# RL6955_IP_SVD register map
Vendor: Realtek
Registers are 32-bit, read-write, reset 0x0 unless marked. A register's access mark holds for its fields unless they carry their own. Offsets are from the block's base; [hi:lo] are bit positions; lines under a group give offsets from that group; {n}, {i} and the like mark numbered series; <NAME> marks a mode.

## SYSTEM_TZ_CTRL_BASE
Base 0x41000000
Same registers: LP_SYS_1 0x41000200
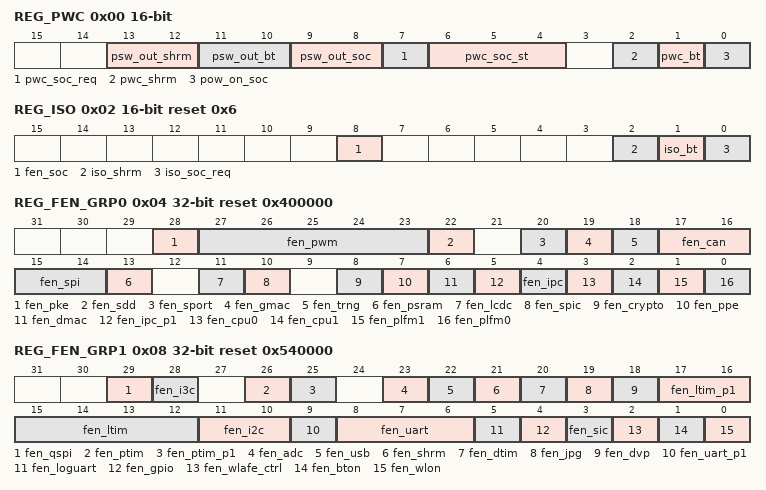
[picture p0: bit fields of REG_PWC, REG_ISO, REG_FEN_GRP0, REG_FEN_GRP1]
0x00 REG_PWC 16-bit access per field
  [13:12] psw_out_shrm ro — ShareMem domain power switch status 1: power on 0: power off Note:there are two group
  [11:10] psw_out_bt ro — BT domain power switch status 1: power on 0: power off Note:there are two group
  [9:8] psw_out_soc ro — SOC domain power switch status 1: power on 0: power off Note:there are two group
  [7] pwc_soc_req ro — pwc soc req arb result
  [6:4] pwc_soc_st ro — pwc soc arb result state
  [2] pwc_shrm rw — BT share mem power cut control 1: Enable BT share mem power (mux + mbis + cell) 0: Disable
  [1] pwc_bt rw — This is BT function total power cut control 1: Enable BT power cut 0: Disable
  [0] pow_on_soc rw — 1:SYS PMC request to enable HP SOC power cut and diable ISO 0: SYS PMC request to disable HP SOC power cut and enable ISO
0x02 REG_ISO 16-bit access per field reset 0x6
  [8] fen_soc rw — 1: enable hs soc sytem 0: disable hs soc system (Note: used as soc power on reset)
  [2] iso_shrm rw — 1: isolate signals from PD_SHRM to other power domain 0: release iso
  [1] iso_bt rw — 1: isolate signals from PD_BT to other power domain 0: release iso
  [0] iso_soc_req ro — isolate signals from PD_SOC to other power domain. It is arb result
0x04 REG_FEN_GRP0 reset 0x400000
  [28] fen_pke — 1: enable pke module 0: reset No use
  [27:23] fen_pwm — 1: enable PWM TIMER function 0: disable [4:1]:pwm [0]:pulse
  [22] fen_sdd — 1: enable sdio device function 0: disable
  [20] fen_sport — 1: enable SPORT function 0: disable
  [19] fen_gmac — 1: enable ppe module 0: reset No use
  [18] fen_trng — 1: enable TRNG function 0: disable
  [17:16] fen_can — 1: enable can0/1 module 0: reset No use
  [15:14] fen_spi — 1: enable SPI1 function 0: disable
  [13] fen_psram — 1: enable PSRAM function 0: disable
  [11] fen_lcdc — 1: enable ppe module 0: reset No use
  [10] fen_spic — Flash spic function enable 1: enable flash 0: disable flash
  [8] fen_crypto — 1: enable IPSEC (AES + HMAC) function 0: disable
  [7] fen_ppe — 1: enable ppe module 0: reset No use
  [6] fen_dmac — 1: enable GDMA function 0: disable
  [5] fen_ipc_p1 — 1: enable IPC function 0: reset
  [4] fen_ipc — 1: enable IPC function 0: reset
  [3] fen_cpu0 — 1: enable cpu0 (KM4TZ) 0: reset
  [2] fen_cpu1 — 1: enable cpu1 (KM4NS) 0: reset
  [1] fen_plfm1 — 1: enable platform1 0: reset
  [0] fen_plfm0 — 1: enable platform0 0: reset
0x08 REG_FEN_GRP1 reset 0x540000
  [29] fen_qspi — 1: enable qspi function 0: disable
  [28] fen_i3c — 1: enable i3c function 0: disable
  [26] fen_ptim — pmc_timer function enable 1: enable 0: disable
  [25] fen_ptim_p1 — pmc_timer function enable 1: enable 0: disable
  [23] fen_adc — lp adc function enable 1: enable 0: disable
  [22] fen_usb — usb core function enable 1: enable 0: disable
  [21] fen_shrm — BT share memory function enable 1: enable 0: disable Note:this is same as PD_SHRM power reset
  [20] fen_dtim — Debug timer function enable 1: enable 0: disable
  [19] fen_jpg — mjpeg function enable 1: enable 0: disable
  [18] fen_dvp — dvp function enable 1: enable 0: disable
  [17:16] fen_ltim_p1 — Basic Timer4-5 function enable for plfm1 1: enable 0: disable
  [15:12] fen_ltim — Basic Timer0-3 function enable for plfm0 1: enable 0: disable
  [11:10] fen_i2c — I2C1 function enable 1: enable 0: disable
  [9] fen_uart_p1 — Uart function enable for BT 1: enable 0: disable
  [8:6] fen_uart — Uart function enable 1: enable 0: disable
  [5] fen_loguart — Uartlog function enable 1: enable 0: disable
  [4] fen_gpio — SGPIO function enable 1: enable 0: disable
  [3] fen_sic — 1: enable SIC function 0: reset
  [2] fen_wlafe_ctrl — WL RFAFE control function enable 1: enable 0: disable
  [1] fen_bton — BTON function enable 1: enable 0: disable
  [0] fen_wlon — WLON function enable 1: enable 0: disable
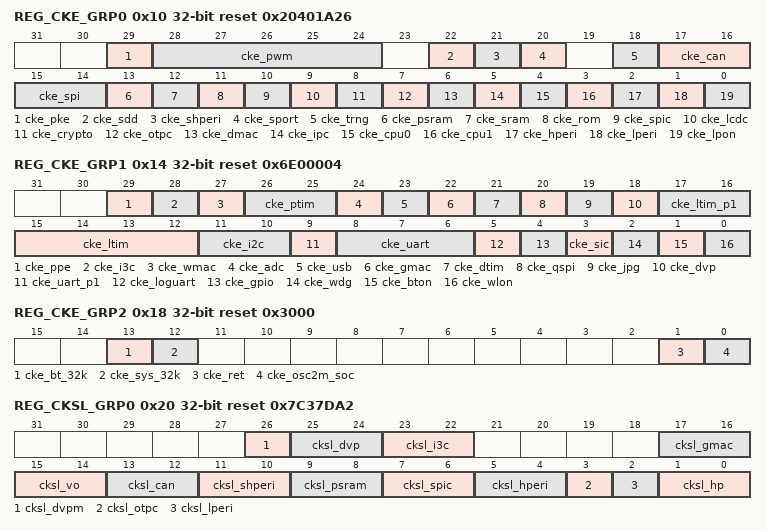
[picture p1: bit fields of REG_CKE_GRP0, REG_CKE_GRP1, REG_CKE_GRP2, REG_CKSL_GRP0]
0x10 REG_CKE_GRP0 reset 0x20401A26
  [29] cke_pke — 1: enable pke clk 0: reset No use
  [28:24] cke_pwm — 1: Enable PWM TIMER clock 0: Disable [1] : pwm timer [0] : pulse timer
  [22] cke_sdd — 1: Enable sdio dev clock 0: Disable
  [21] cke_shperi — 1: Enable shperi clock 0: Disable
  [20] cke_sport — 1: Enable sport clock 0: Disable
  [18] cke_trng — 1: Enable trng bus clock 0: Disable
  [17:16] cke_can — 1: Enable can0/1 bus clock 0: Disable
  [15:14] cke_spi — 1: Enable spi clock 0: Disable
  [13] cke_psram — 1: Enable PSRAM pll divider clock 0: Disable
  [12] cke_sram — 1: Enable sram clock 0: Disable
  [11] cke_rom — 1: Enable rom clock 0: Disable
  [10] cke_spic — 1: Enable FLASH pll divider clock 0: Disable
  [9] cke_lcdc — 1: Enable lcdc pll clock 0: Disable Note: lcdc/mipi all use this cke
  [8] cke_crypto — 1: Enable ipsec (AES + HMAC) clock 0: Disable
  [7] cke_otpc — 1: Enable OTPC clock 0: Disable
  [6] cke_dmac — 1: Enable GDMA0 clock 0: Disable
  [5] cke_ipc — 1: Enable IPC clock 0: Disable
  [4] cke_cpu0 — 1: Enable hp KM4 cpu0 clock 0: Disable
  [3] cke_cpu1 — 1: Enable lp KM4 cpu1 clock 0: Disable
  [2] cke_hperi — 1: Enable HPERI pll divider clock 0: Disable
  [1] cke_lperi — 1: Enable peri_lclk clock all 0: Disable
  [0] cke_lpon — 1.Enable lpon clk 0: Disable Note: this bit is controlled HW PMC, SW shall not modify
0x14 REG_CKE_GRP1 reset 0x6E00004
  [29] cke_ppe — 1: Enable ppe clock 0: Disable
  [28] cke_i3c — 1: Enable i3c clock 0: Disable
  [27] cke_wmac — 1: Enable WMAC AXI and AHB bus clock 0: Disable
  [26:25] cke_ptim — 1: Enable pmc timer clock 0: Disable
  [24] cke_adc — 1: Enable LS ADC clock 0: Disable
  [23] cke_usb — 1: Enable usb core clock 0: Disable
  [22] cke_gmac — 1: Enable gmac clock 0: Disable
  [21] cke_dtim — 1: Enable LS dtim clk 0: Disable
  [20] cke_qspi — 1: Enable qsip clock 0: Disable
  [19] cke_jpg — 1: Enable jpg clock 0: Disable
  [18] cke_dvp — 1: Enable dvp clock 0: Disable
  [17:16] cke_ltim_p1 — LS basic Timer4-5 clk enable for plfm1 0: Disable
  [15:12] cke_ltim — LS basic Timer0-3 clk enable 0: Disable
  [11:10] cke_i2c — 1: Enable HS I2C0 clock 0: Disable [1]: i2c1 [0]: i2c0
  [9] cke_uart_p1 — 1: Enable Uart clock for uart3 0: Disable
  [8:6] cke_uart — 1: Enable Uart clock 0: Disable
  [5] cke_loguart — 1: Enable Uartlog clock 0: Disable
  [4] cke_gpio — 1: Enable GPIO clock 0: Disable
  [3] cke_sic — 1: Enable SIC clock 0: Disable
  [2] cke_wdg — 1: Enable wdg bus clock 0: Disable
  [1] cke_bton — 1: Enable BTON clock 0: Disable
  [0] cke_wlon — 1: Enable WLON clock 0: Disable
0x18 REG_CKE_GRP2 reset 0x3000
  [13] cke_bt_32k — 1.Enable bt 32k enable 0: Disable
  [12] cke_sys_32k — 1.Enable system/wifi 32k enable 0: Disable
  [1] cke_ret — 1.Enable Some IP's clock who has retention function when pmc state change 0: Disable Note: this bit is controlled HW PMC, SW shall not modify
  [0] cke_osc2m_soc — 1.Enable 2M clk path for soc clk 0: Disable Note: this bit is controlled HW PMC, SW shall not modify
0x20 REG_CKSL_GRP0 reset 0x7C37DA2
  [26] cksl_dvpm — dvpm clock select ##0: sys_pll ##1: usb_pll
  [25:24] cksl_dvp — dvp clock select ##x0: xtal ##01: sys_pll ##11: usb_pll
  [23:22] cksl_i3c — i3c clock select ##x0: xtal ##01: sys_pll ##11: usb_pll
  [17:16] cksl_gmac — gmac clock select ##x0: ext50m ##01: sys_pll( 400M for gmac path) ##11: usb_pll
  [15:14] cksl_vo — vo clock select ##x0: xtal ##01: sys_pll ##11: usb_pll
  [13:12] cksl_can — can clock select ##x0: xtal ##01: sys_pll ##11: usb_pll
  [11:10] cksl_shperi — peri_shclk clock select ##x0: xtal ##01: sys_pll ##11: usb_pll
  [9:8] cksl_psram — psram clock select ##x0: xtal ##01: sys_pll ##11: usb_pll
  [7:6] cksl_spic — spic clock select ##x0: xtal ##01: sys_pll ##11: usb_pll
  [5:4] cksl_hperi — hperi clock seletion ##x0: xtal ##01: sys_pll ##11: usb_pll
  [3] cksl_otpc — otpc clock selection ##0: osc4m ##1: xtal Note: this bit will be set by pmc auto, when SW use otp, it will be set to 1
  [2] cksl_lperi — LPERI clock select ##0: osc4m ##1: xtal_40m
  [1:0] cksl_hp — HP clock select,used for KM4 and sram ##x0: xtal ##01: sys_pll ##11: usb_pll
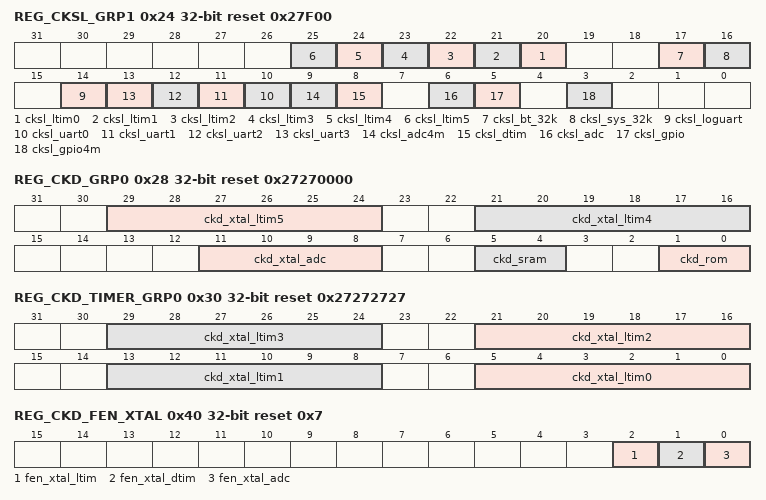
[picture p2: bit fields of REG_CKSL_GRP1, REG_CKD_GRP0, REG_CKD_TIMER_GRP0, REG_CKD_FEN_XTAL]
0x24 REG_CKSL_GRP1 reset 0x27F00
  [n+20] cksl_ltim{n} (n=0..5) — LS timer {n} clock source select ##0: sdm32k ##1: xtal Note:using XTAL divider out , which can be 40M/N (N=2~63)
  [17] cksl_bt_32k — BT 32k clk source selection ##0: osc131k ##1: xtal312p5k
  [16] cksl_sys_32k — system/wifi 32k clk source selection ##0: osc131k ##1: xtal312p5k
  [14] cksl_loguart — Select loguart's input clock ##0: osc4m ##1: xtal
  [n+10] cksl_uart{n} (n=0..3) — Select uart's input rx clock ##0: osc2m ##1: xtal Note:tx input clock is always xtal , and divided in uart IP
  [9] cksl_adc4m — lp adc 4m clk selection ##0: osc4m ##1: xtal Note:when select xtal , it must set divider
  [8] cksl_dtim — dtim clock selection ##0: sdm32k ##1: xtal Note:when select to xtal, it will divided to 1M fixed
  [6] cksl_adc — ADC INT clock selection ##0: bus_clk ##1: ip_clk
  [5] cksl_gpio — GPIO INT clock selecton: ##0: bus_clk ##1: ip_clk
  [3] cksl_gpio4m — gpio ip using 4m clk selection ##0: sdm32k ##1: osc4m
0x28 REG_CKD_GRP0 reset 0x27270000
  [29:24] ckd_xtal_ltim5 — LS timer xtal clock divider when cksl_ltim = 1 0: not support 1: div2 n: divider is n+1 DIV_MIN:1
  [21:16] ckd_xtal_ltim4 — LS timer xtal clock divider when cksl_ltim = 1 0: not support 1: div2 n: divider is n+1 DIV_MIN:1
  [11:8] ckd_xtal_adc — xtal 4m divider for adc Default is /1 which output 40M
  [5:4] ckd_sram — sram clock divider, it is based on hp_clk 0: div1 1: div2 2: div3 3/other: divider by this value + 1 DIV_MIN:0
  [1:0] ckd_rom — rom clock divider, it is based on hp_clk 0: div1 1: div2 2: div3 3/other: divider by this value + 1 DIV_MIN:0
0x30 REG_CKD_TIMER_GRP0 reset 0x27272727
  [8n+5:8n] ckd_xtal_ltim{n} (n=0..3) — LS timer xtal clock divider when cksl_ltim = 1 0: not support 1: div2 n: divider is n+1 DIV_MIN:1
0x34 REG_CKD_TIMER_GRP1 reset 0x270000
  [21:16] ckd_xtal_dtim — xtal 1m divider for dtim Default is /40 which output 1M
0x40 REG_CKD_FEN_XTAL reset 0x7
  [2] fen_xtal_ltim — enable xtal divider for ltim[5:0] use 1:enable 0:disable
  [1] fen_xtal_dtim — enable xtal divider for dtim use 1:enable 0:disable
  [0] fen_xtal_adc — enable xtal divider for adc use 1:enable 0:disable
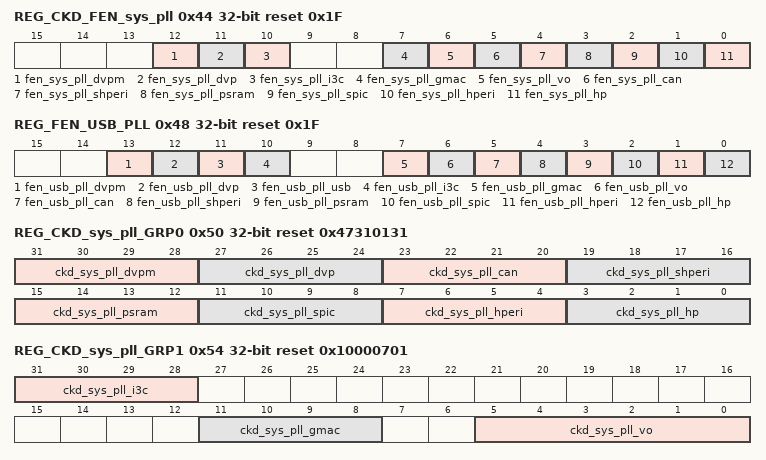
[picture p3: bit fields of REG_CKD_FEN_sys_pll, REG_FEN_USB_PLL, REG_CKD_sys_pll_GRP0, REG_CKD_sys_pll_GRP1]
0x44 REG_CKD_FEN_sys_pll reset 0x1F
  [12] fen_sys_pll_dvpm — sys_pll_divider for dvpm enable 1:enable 0:disable
  [11] fen_sys_pll_dvp — sys_pll_divider for dvp enable 1:enable 0:disable
  [10] fen_sys_pll_i3c — sys_pll_divider for i3c enable 1:enable 0:disable
  [7] fen_sys_pll_gmac — sys_pll_divider for gmac enable 1:enable 0:disable
  [6] fen_sys_pll_vo — sys_pll_divider for vo enable 1:enable 0:disable
  [5] fen_sys_pll_can — sys_pll_divider for can 1:enable 0:disable
  [4] fen_sys_pll_shperi — sys_pll_divider for shperi enable 1:enable 0:disable
  [3] fen_sys_pll_psram — sys_pll_divider for psram enable 1:enable 0:disable
  [2] fen_sys_pll_spic — sys_pll_divider for spic enable 1:enable 0:disable
  [1] fen_sys_pll_hperi — sys_pll_divider for hperi enable 1:enable 0:disable
  [0] fen_sys_pll_hp — sys_pll_divider for hp enable 1:enable 0:disable
0x48 REG_FEN_USB_PLL reset 0x1F
  [13] fen_usb_pll_dvpm — usb_pll_divider for dvpm enable 1:enable 0:disable
  [12] fen_usb_pll_dvp — usb_pll_divider for dvp enable 1:enable 0:disable
  [11] fen_usb_pll_usb — usb_pll divider for usb utim enable 1:enable 0:disable
  [10] fen_usb_pll_i3c — usb_pll_divider for i3c enable 1:enable 0:disable
  [7] fen_usb_pll_gmac — usb_pll_divider for gmac enable 1:enable 0:disable
  [6] fen_usb_pll_vo — usb_pll_divider for vo enable 1:enable 0:disable
  [5] fen_usb_pll_can — usb_pll_divider for can 1:enable 0:disable
  [4] fen_usb_pll_shperi — usb_pll_divider for shperi enable 1:enable 0:disable
  [3] fen_usb_pll_psram — usb_pll_divider for psram enable 1:enable 0:disable
  [2] fen_usb_pll_spic — usb_pll_divider for spic enable 1:enable 0:disable
  [1] fen_usb_pll_hperi — usb_pll_divider for hperi enable 1:enable 0:disable
  [0] fen_usb_pll_hp — usb_pll_divider for hp enable 1:enable 0:disable
0x50 REG_CKD_sys_pll_GRP0 reset 0x47310131
  [31:28] ckd_sys_pll_dvpm — sys_pll divider for shperi 0: div1 1: div2 ... DIV_MIN:0
  [27:24] ckd_sys_pll_dvp — sys_pll divider for shperi 0: div1 1: div2 ... DIV_MIN:0
  [23:20] ckd_sys_pll_can — sys_pll divider for can 0: div1 1: div2 ... Note: default 320M/3=106M DIV_MIN:0
  [19:16] ckd_sys_pll_shperi — sys_pll divider for shperi 0: div1 1: div2 ... DIV_MIN:0
  [15:12] ckd_sys_pll_psram — sys_pll divider for psram 0: Not support 1: div2 ... DIV_MIN:1
  [11:8] ckd_sys_pll_spic — sys_pll divider for spic 0: Not support 1: div2 ... DIV_MIN:1
  [7:4] ckd_sys_pll_hperi — sys_pll divider for hperi 0: Not support 1: div2 ... DIV_MIN:1
  [3:0] ckd_sys_pll_hp — sys_pll divider for hp 0: Not support 1: div2 ... DIV_MIN:1
0x54 REG_CKD_sys_pll_GRP1 reset 0x10000701
  [31:28] ckd_sys_pll_i3c — sys_pll divider for i3c clk 0: div1 1: div2 ... Note: default 200M (for i3c afe clock select 400M) DIV_MIN:0
  [11:8] ckd_sys_pll_gmac — sys_pll divider for vo/panel clk 0: div1 1: div2 ... Note: fix to 50M (for gmac afe clock select 400M) DIV_MIN:0
  [5:0] ckd_sys_pll_vo — sys_pll divider for vo/panel clk 0: div1 1: div2 ... Note: max 200M DIV_MIN:0
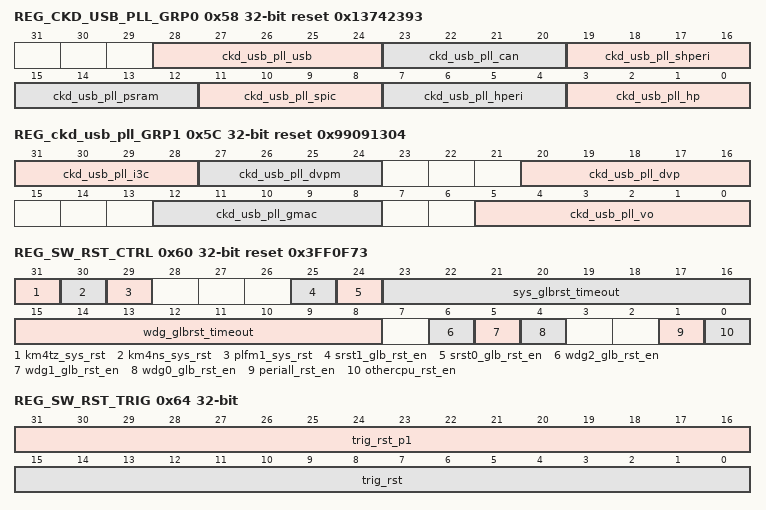
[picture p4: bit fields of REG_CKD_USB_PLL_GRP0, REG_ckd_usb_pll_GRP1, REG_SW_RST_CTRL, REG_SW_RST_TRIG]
0x58 REG_CKD_USB_PLL_GRP0 reset 0x13742393
  [28:24] ckd_usb_pll_usb — usb_pll divider for usb utmi , default 48M 0: div1 1: div2 ... Note: default 960M/8=120M DIV_MIN:0
  [23:20] ckd_usb_pll_can — usb_pll divider for can 0: div1 1: div2 ... Note: default 960M/8=120M DIV_MIN:0
  [19:16] ckd_usb_pll_shperi — usb_pll divider for shperi 0: div1 1: div2 ... DIV_MIN:0
  [15:12] ckd_usb_pll_psram — usb_pll divider for psram, special 400M pll input 0: div1 1: div2 ... DIV_MIN:0
  [11:8] ckd_usb_pll_spic — usb_pll divider for spic 0: div1 1: div2 ... DIV_MIN:0
  [7:4] ckd_usb_pll_hperi — usb_pll divider for hperi 0: div1 1: div2 ...
  [3:0] ckd_usb_pll_hp — usb_pll divider for hp 0: div1 1: div2 ... DIV_MIN:0
0x5C REG_ckd_usb_pll_GRP1 reset 0x99091304
  [31:28] ckd_usb_pll_i3c — usb_pll divider for i3c clk 0: div1 1: div2 ... DIV_MIN:0
  [27:24] ckd_usb_pll_dvpm — usb_pll divider for sdh clk 0: div1 1: div2 ... DIV_MIN:0
  [20:16] ckd_usb_pll_dvp — usb_pll divider for dvp clk 0: div1 1: div2 ... DIV_MIN:0
  [12:8] ckd_usb_pll_gmac — usb_pll divider for gmac, Note: output must fix to 50M.
  [5:0] ckd_usb_pll_vo — usb_pll divider for vo/panel 0: div1 1: div2 ... Note: max 200M DIV_MIN:0
0x60 REG_SW_RST_CTRL reset 0x3FF0F73
  [31] km4tz_sys_rst — Only when REG_SW_RST_TRIG is 0x96969696 , this reg can be write
  [30] km4ns_sys_rst — Only when REG_SW_RST_TRIG is 0x96969696 , this reg can be write
  [29] plfm1_sys_rst — Only when REG_SW_RST_TRIG is 0x96969696 , this reg can be write
  [25] srst1_glb_rst_en — 1.system reset1 will reset all syson IP and local CPU1(km4ns) 0.system reset0 will reset local CPU1(km4ns)
  [24] srst0_glb_rst_en — 1.system reset0 will reset all syson IP and local CPU0(km4tz) 0.system reset0 will reset local CPU0(km4tz)
  [23:16] sys_glbrst_timeout — If system glb rst en is disable , system reset will reset its local cpu only . but if bus is hang , it will trigger global reset also . HW will wait local CPU's status , if it is not in IDLE in a threshold time, it will trigger global reset . Note : This value must set > 1 , it is base on 4M clock cycle .
  [15:8] wdg_glbrst_timeout — If wdg's glb rst en is disable , wdg reset will reset its local cpu only . but if bus is hang , it will trigger global reset also . HW will wait local CPU's status , if it is not in IDLE in a threshold time, it will trigger global reset . Note : This value must set > 1 , it is base on 32k clock cycle .
  [6] wdg2_glb_rst_en — 1.wdg2 will reset all syson IP and local CPU 0.wdg2 will reset local CPU and itself Note: wdg2 's local CPU is CPU0
  [5] wdg1_glb_rst_en — 1.wdg1 will reset all syson IP and local CPU 0.wdg1 will reset local CPU and itself Note: wdg1 's local CPU is CPU0
  [4] wdg0_glb_rst_en — 1.wdg0 will reset all syson IP and local CPU 0.wdg0 will reset local CPU and itself Note: wdg0 's local CPU is CPU1
  [1] periall_rst_en — 1. warm reset request by one cpu will reset all peri and local cpu 0. warm reset request by one cpu will only reset local cpu Note : peri rst will use sysrst mst also
  [0] othercpu_rst_en — 1. warm reset request by one cpu will reset other cpu's core and local cpu 0. warm reset request by one cpu will only reset local cpu
0x64 REG_SW_RST_TRIG
  [31:16] trig_rst_p1 — System reset trigger register Write 0x96969696 to enable the write of reset control Write 0x69696969 will trigger the system if REG_SW_RST_CTRL set .
  [15:0] trig_rst — System reset trigger register Write 0x96969696 to enable the write of reset control Write 0x69696969 will trigger the system if REG_SW_RST_CTRL set .
0x68 REG_BOOT_REASON_SW
  [31:0] dummy
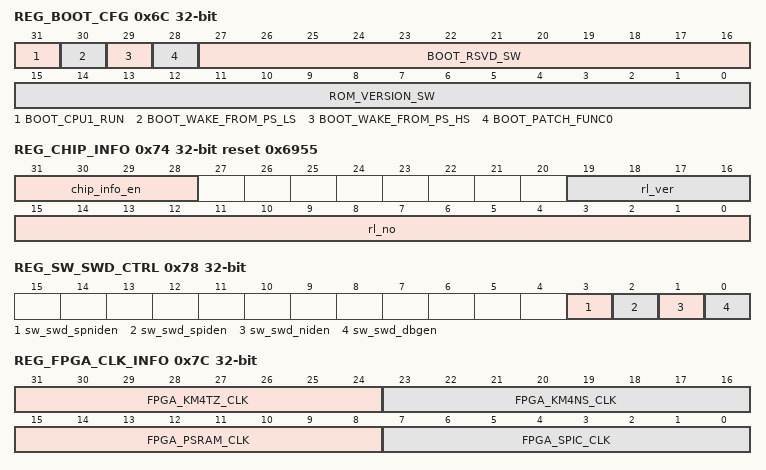
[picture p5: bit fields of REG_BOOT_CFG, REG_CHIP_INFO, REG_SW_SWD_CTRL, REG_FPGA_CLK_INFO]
0x6C REG_BOOT_CFG
  [31] BOOT_CPU1_RUN, [30] BOOT_WAKE_FROM_PS_LS, [29] BOOT_WAKE_FROM_PS_HS, [28] BOOT_PATCH_FUNC0, [27:16] BOOT_RSVD_SW, [15:0] ROM_VERSION_SW
0x70 REG_SW_PATCH
  [31:0] sw_patch_saddr — SW patch code start addr. OTP physical addr 0x500-0x6FF will autoload to this addr .
0x74 REG_CHIP_INFO access per field reset 0x6955
  [31:28] chip_info_en rw — Enable Internal Chip Information display.(Don't move 0x74 address , for code is not auto-gen) 0xA: enable. Others: disable. Note: CHIP_INFO can be read only if CHIP_INFO_EN[3:0]=0xA, otherwise the read result will return 0x0.
  [19:16] rl_ver ro — CHIP cut verison : 0: A-cut 1: B-cut ...
  [15:0] rl_no ro — CHIP RL NUMBER : 0x6955 Note: this field also used by FPGA or Simulation . 0xFFFF: FPGA 0XFFFE: PXP 0xFFF0: IMG Simulation 0 (when simulation , disable loguart for speedup, disable calibration)
0x78 REG_SW_SWD_CTRL
  [3] sw_swd_spniden, [2] sw_swd_spiden, [1] sw_swd_niden, [0] sw_swd_dbgen
0x7C REG_FPGA_CLK_INFO ro
  [31:24] FPGA_KM4TZ_CLK — FPGA KM4TZ clock
  [23:16] FPGA_KM4NS_CLK — FPGA KM4NS clock
  [15:8] FPGA_PSRAM_CLK — FPGA PSRAM clock
  [7:0] FPGA_SPIC_CLK — FPGA SPIC clock
0x80 REG_KM4_XO_CTRL0
  [31:0] init_xo_base
0x84 REG_KM4_XO_CTRL1
  [31:0] init_xo_top
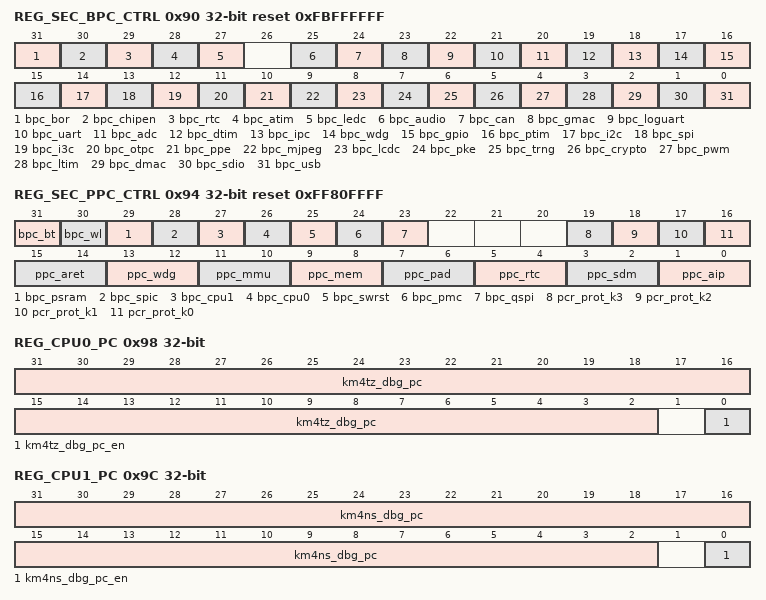
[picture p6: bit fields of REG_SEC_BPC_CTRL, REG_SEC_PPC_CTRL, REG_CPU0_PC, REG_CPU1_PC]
0x90 REG_SEC_BPC_CTRL reset 0xFBFFFFFF
  [31] bpc_bor — Select IP controller source : bor 1:control by nonsec zone 0:control by secure zone
  [30] bpc_chipen — Select IP controller source : chipen 1:control by nonsec zone 0:control by secure zone
  [29] bpc_rtc — Select IP controller source : rtc 1:control by nonsec zone 0:control by secure zone
  [28] bpc_atim — Select IP controller source : atim 1:control by nonsec zone 0:control by secure zone
  [27] bpc_ledc — Select IP controller source : ledc 1:control by nonsec zone 0:control by secure zone
  [25] bpc_audio — Select IP controller source : audio 1:control by nonsec zone 0:control by secure zone
  [24] bpc_can — Select IP controller source : can 1:control by nonsec zone 0:control by secure zone
  [23] bpc_gmac — Select IP controller source : gmac 1:control by nonsec zone 0:control by secure zone
  [22] bpc_loguart — Select IP controller source : loguart 1:control by nonsec zone 0:control by secure zone
  [21] bpc_uart — Select IP controller source : uart 1:control by nonsec zone 0:control by secure zone
  [20] bpc_adc — Select IP controller source : adc4m 1:control by nonsec zone 0:control by secure zone
  [19] bpc_dtim — Select IP controller source : dtim 1:control by nonsec zone 0:control by secure zone
  [18] bpc_ipc — Select IP controller source : ipc 1:control by nonsec zone 0:control by secure zone
  [17] bpc_wdg — Select IP controller source : wdg 1:control by nonsec zone 0:control by secure zone
  [16] bpc_gpio — Select IP controller source : gpio 1:control by nonsec zone 0:control by secure zone
  [15] bpc_ptim — Select IP controller source : ptim 1:control by nonsec zone 0:control by secure zone
  [14] bpc_i2c — Select IP controller source : i2c 1:control by nonsec zone 0:control by secure zone
  [13] bpc_spi — Select IP controller source : spi 1:control by nonsec zone 0:control by secure zone
  [12] bpc_i3c — Select IP controller source : irda 1:control by nonsec zone 0:control by secure zone
  [11] bpc_otpc — Select IP controller source : otpc 1:control by nonsec zone 0:control by secure zone
  [10] bpc_ppe — Select IP controller source : ppe 1:control by nonsec zone 0:control by secure zone
  [9] bpc_mjpeg — Select IP controller source : mjpeg 1:control by nonsec zone 0:control by secure zone
  [8] bpc_lcdc — Select IP controller source : lcdc 1:control by nonsec zone 0:control by secure zone
  [7] bpc_pke — Select IP controller source : pke 1:control by nonsec zone 0:control by secure zone
  [6] bpc_trng — Select IP controller source : trng 1:control by nonsec zone 0:control by secure zone
  [5] bpc_crypto — Select IP controller source : crypto 1:control by nonsec zone 0:control by secure zone
  [4] bpc_pwm — Select IP controller source : pwm 1:control by nonsec zone 0:control by secure zone
  [3] bpc_ltim — Select IP controller source : ltim 1:control by nonsec zone 0:control by secure zone
  [2] bpc_dmac — Select IP controller source : dmac 1:control by nonsec zone 0:control by secure zone
  [1] bpc_sdio — Select IP controller source : sdio 1:control by nonsec zone 0:control by secure zone
  [0] bpc_usb — Select IP controller source : usb 1:control by nonsec zone 0:control by secure zone
0x94 REG_SEC_PPC_CTRL reset 0xFF80FFFF
  [31] bpc_bt — Select IP controller source : bt 1:control by nonsec zone 0:control by secure zone
  [30] bpc_wl — Select IP controller source : wl 1:control by nonsec zone 0:control by secure zone
  [29] bpc_psram — Select IP controller source : psram 1:control by nonsec zone 0:control by secure zone
  [28] bpc_spic — Select IP controller source : spic 1:control by nonsec zone 0:control by secure zone
  [27] bpc_cpu1 — Select IP controller source : cpu1 1:control by nonsec zone 0:control by secure zone
  [26] bpc_cpu0 — Select IP controller source : cpu0 1:control by nonsec zone 0:control by secure zone
  [25] bpc_swrst — Select IP controller source : rst 1:control by nonsec zone 0:control by secure zone
  [24] bpc_pmc — Select IP controller source : pmc 1:control by nonsec zone 0:control by secure zone
  [23] bpc_qspi — Select IP controller source : qspi 1:control by nonsec zone 0:control by secure zone
  [19] pcr_prot_k3 — Retention Mem last forth 256 bit protect 0: read and write , 1 : read only
  [18] pcr_prot_k2 — Retention Mem last third 256 bit protect 0: read and write , 1 : read only
  [17] pcr_prot_k1 — Retention Mem last second 256 bit protect 0: read and write , 1 : read only
  [16] pcr_prot_k0 — Retention Mem last 256 bit protect (located in last 256bit of retention memory) 0: read and write , 1 : read only
  [15:14] ppc_aret — IP slave port R/W secure ctrl [0]: wr prot ctrl , 0: secure only , 1: both [1]: rd prot ctrl , 0:secure only , 1:both
  [13:12] ppc_wdg — IP slave port R/W secure ctrl [0]: wr prot ctrl , 0: secure only , 1: both [1]: rd prot ctrl , 0:secure only , 1:both
  [11:10] ppc_mmu — IP slave port R/W secure ctrl [0]: wr prot ctrl , 0: secure only , 1: both [1]: rd prot ctrl , 0:secure only , 1:both
  [9:8] ppc_mem — IP slave port R/W secure ctrl [0]: wr prot ctrl , 0: secure only , 1: both [1]: rd prot ctrl , 0:secure only , 1:both
  [7:6] ppc_pad — IP slave port R/W secure ctrl [0]: wr prot ctrl , 0: secure only , 1: both [1]: rd prot ctrl , 0:secure only , 1:both Note:this control both of pinmux and ledc, for they are in same reset domain.
  [5:4] ppc_rtc — IP slave port R/W secure ctrl [0]: wr prot ctrl , 0: secure only , 1: both [1]: rd prot ctrl , 0:secure only , 1:both
  [3:2] ppc_sdm — IP slave port R/W secure ctrl [0]: wr prot ctrl , 0: secure only , 1: both [1]: rd prot ctrl , 0:secure only , 1:both
  [1:0] ppc_aip — IP slave port R/W secure ctrl [0]: wr prot ctrl , 0: secure only , 1: both [1]: rd prot ctrl , 0:secure only , 1:both
0x98 REG_CPU0_PC access per field
  [31:2] km4tz_dbg_pc ro — cpu0 pc value for debug which is pc[31:2]
  [0] km4tz_dbg_pc_en rw — debug enable
0x9C REG_CPU1_PC access per field
  [31:2] km4ns_dbg_pc ro — cpu1 pc value for debug which is pc[31:2]
  [0] km4ns_dbg_pc_en rw — debug enable
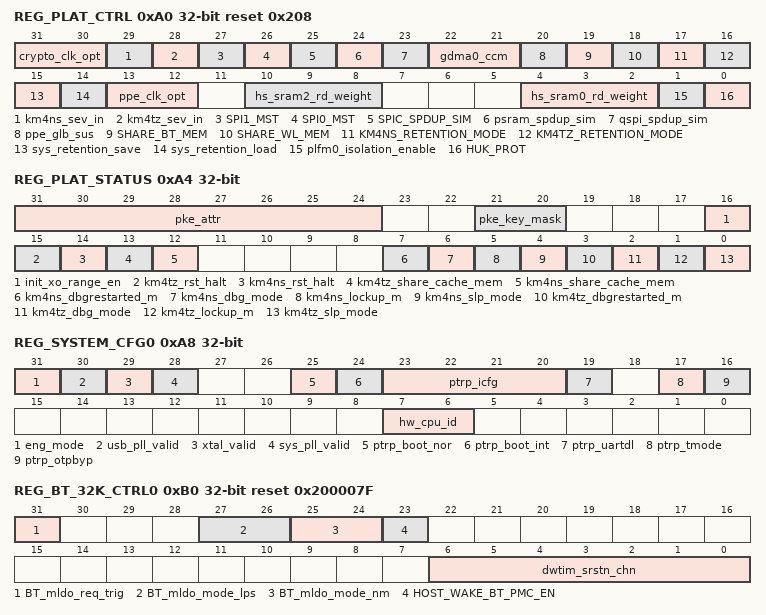
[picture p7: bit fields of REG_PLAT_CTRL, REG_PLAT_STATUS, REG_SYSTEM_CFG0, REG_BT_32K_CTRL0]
0xA0 REG_PLAT_CTRL reset 0x208
  [31:30] crypto_clk_opt — 1X: always ON 01: always OFF 00: controlled by internal ICG
  [29] km4ns_sev_in — cpu1 sev input, posedge of this bit will trig cpu1 event
  [28] km4tz_sev_in — cpu0 sev input, posedge of this bit will trig CPU0 event
  [27] SPI1_MST — 1: SPI1 used as master 0: SPI1 used as slaver
  [26] SPI0_MST — 1: SPI0 used as master 0: SPI0 used as slaver
  [25] SPIC_SPDUP_SIM — 1: SPIC will wait 256 spic_clk cycles before ready 0: SPIC will wait 2^16 spic_clk cycles before ready
  [24] psram_spdup_sim — psramc simulatin speedup enable. Nouse because config form not specified .
  [23] qspi_spdup_sim — qspi simulation speedup enable
  [22:21] gdma0_ccm — GDMA0 clock control mode
  [20] ppe_glb_sus — Assert this bit to suspend PPE, active high
  [19] SHARE_BT_MEM — 1: Enable KM4 to share BT memory
  [18] SHARE_WL_MEM — 1: Enable KM4 to share WL memory
  [17] KM4NS_RETENTION_MODE — 1: Enable, when CPU1 reset, cache will not be cleared 0: Disable, when CPU1 reset, cache will be cleared by HW
  [16] KM4TZ_RETENTION_MODE — 1: Enable, when CPU0 reset, cache will not be cleared 0: Disable, when CPU0 reset, cache will be cleared by HW
  [15] sys_retention_save — 1: save data
  [14] sys_retention_load — 1: restore data
  [13:12] ppe_clk_opt — ppe clock option
  [10:8] hs_sram2_rd_weight — Excuted read command number continuously if both read and write command reached This is for bt/wl share_ram
  [4:2] hs_sram0_rd_weight — Excuted read command number continuously if both read and write command reached This is for hs_ram 512K
  [1] plfm0_isolation_enable — 1:plfm1 -> plfm0 access will be blocked
  [0] HUK_PROT — 0: only cpu can read HUK key 1: no one can read HUK key This bit will be latch to high when it was write to 1 until reset again .
0xA4 REG_PLAT_STATUS access per field
  [31:24] pke_attr rw — pke key secure attribute
  [21:20] pke_key_mask rw — pke key0 mask mode 00:no mask 01:mask high 128bit 10:mask high 256bit 11:no mask
  [16] init_xo_range_en rw
  [15] km4tz_rst_halt rw
  [14] km4ns_rst_halt rw
  [13] km4tz_share_cache_mem rw — 0: km4tz cache memory used as cache 1: km4tz cache memory used as dtcm
  [12] km4ns_share_cache_mem rw — 0: km4ns cache memory used as cache 1: km4ns cache memory used as dtcm
  [7] km4ns_dbgrestarted_m ro — km4ns debug restart status
  [6] km4ns_dbg_mode ro — km4ns halt status
  [5] km4ns_lockup_m ro — km4ns lockup status
  [4] km4ns_slp_mode ro — km4ns sleep status
  [3] km4tz_dbgrestarted_m ro — km4tz debug restart status
  [2] km4tz_dbg_mode ro — km4tz halt status
  [1] km4tz_lockup_m ro — km4tz lockup status
  [0] km4tz_slp_mode ro — km4tz sleep status
0xA8 REG_SYSTEM_CFG0 ro
  [31] eng_mode — Indicate PKG_ENG_SEL pad value 0: normal package; 1: engineering mode
  [30] usb_pll_valid — Indicator usb pll is ready,not used in RL6955
  [29] xtal_valid — Indicator xtal 40M is ready
  [28] sys_pll_valid — Indicator sys pll is ready
  [25] ptrp_boot_nor
  [24] ptrp_boot_int
  [23:20] ptrp_icfg — Trapped ICFG data value 0: normall mode XXXX: the other mode (Test Mode)
  [19] ptrp_uartdl — Power on trapped uart download value 0: Normal boot 1: uartdownload boot TODO: it may be overwrited by efuse autoload
  [17] ptrp_tmode — 0: normal mode 1: test mode
  [16] ptrp_otpbyp — 1: force efuse autoload fail
  [7:6] hw_cpu_id — Different CPU reading this register will return different value. If read by KR4: return 0 If read by KM4: return 1 Other will return 2
0xB0 REG_BT_32K_CTRL0 reset 0x200007F
  [31] BT_mldo_req_trig — level -> pulse. Write to 1 to update BT analog 1.8V LDO request when BT is active (load BT_mldo_mode_nm). need to write 0 before next request
  [27:26] BT_mldo_mode_lps — mem ldo mode slep option 00:off 01:sleep 10:normal + dummy 11:normal + no dummy
  [25:24] BT_mldo_mode_nm — mem ldo mode normal option 00:off 01:sleep 10:normal + dummy 11:normal + no dummy
  [23] HOST_WAKE_BT_PMC_EN — 1: host_wakt_bt will wake bt_misc pmc, and then wake BTTOP (wait SWR/XTAL/PLL ready) 0: host_wakt_bt wake BTTOP and then rif_oscenout wake bt_misc pmc
  [6:0] dwtim_srstn_chn — sw reset for bt dw channel ,active 0 default all channel will release after dw timer function enable
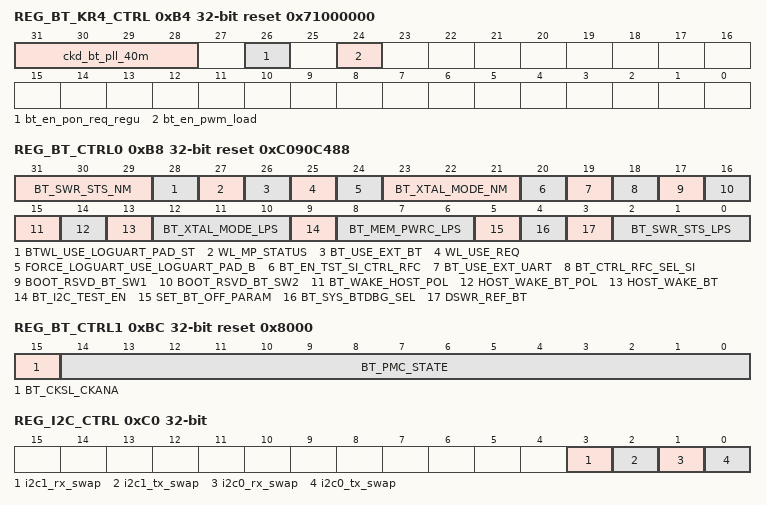
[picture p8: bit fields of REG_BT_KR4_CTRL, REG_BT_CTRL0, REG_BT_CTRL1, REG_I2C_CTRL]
0xB4 REG_BT_KR4_CTRL reset 0x71000000
  [31:28] ckd_bt_pll_40m — pll divider for BT 0: Not support 1: div2 ... DIV_MIN:1
  [26] bt_en_pon_req_regu — 1: enable to change BT regu_sts request during BT active
  [24] bt_en_pwm_load — 1:when bt enter normal , it will enable pwm high loading option 0:pwm loading change effect by bt
0xB8 REG_BT_CTRL0 access per field reset 0xC090C488
  [31:29] BT_SWR_STS_NM rw — SET SWR state when BT in active mode 000: RSVD 001: state1 0.7/PC/PFM 010: state2 0.8/PC/PFM 011: state3 0.9/PC/PFM 100: state4 0.9/SLP/PFM 101: state5 0.9/SLP/PWM 110: state6 0.9/NORM/PWM 111: state7 1.0/NORM/PWM
  [28] BTWL_USE_LOGUART_PAD_ST ro — The state of xor of WL_USE_REQ and BT_USE_REQ. 0: loguart use loguart trx pad 1: bt hci use loguart trx pad
  [27] WL_MP_STATUS rw — Wi-Fi MP status
  [26] BT_USE_EXT_BT rw — 1: select external BT 0: select internal BT
  [25] WL_USE_REQ rw — who uses loguart trx pad depends on the xor of WL_USE_REQ and BT_USE_REQ, wifi can send use request by change the value of WL_USE_REQ
  [24] FORCE_LOGUART_USE_LOGUART_PAD_B rw — Force wifi soc to use loguart pad mandatory if necessary 0: loguart use loguart trx pad 1: who uses loguart trx pad depends on BTWL_USE_LOGUART_PAD_ST
  [23:21] BT_XTAL_MODE_NM rw — SET XTAL state when BT in active mode 000: XTAL OFF 001: XTAL LPS, gating XTAL 40M 010: XTAL LPS, enable XTAL 40M 011: XTAL NM mode 100: XTAL HP mode
  [20] BT_EN_TST_SI_CTRL_RFC rw — 进入Test Mode 8 , 且同時 BT_EN_TST_SI_CTRL_RFC=1 , 才將RFC 端的SI 3 wire交由專線BT_SI_*_TST 控制; 若I2C 想要access RFC,设置BT_EN_TST_SI_CTRL_RFC=0 或者 將BT_SI_ENB_TST pull high(如果BT_SI_ENB_TST 有出 PIN)
  [19] BT_USE_EXT_UART rw — 1: BT use external uart 0: BT use internal uart
  [18] BT_CTRL_RFC_SEL_SI rw — Normal mode 或者Test Mode 2,通过此寄存器选择RFC的控制端. BT_CTRL_RFC_SEL_SI = 1,將RFC 端的SI 3 wire交由專線BT_SI_*_TST 控制;BT_CTRL_RFC_SEL_SI = 0,將RFC 端的SI 3 wire交由 I2C 控制. BT_CTRL_RFC_SEL_SI = 1时,也可通过将BT_SI_ENB_TST pull high,交由PI控制
  [17] BOOT_RSVD_BT_SW1 rw — RSVD for sotfware
  [16] BOOT_RSVD_BT_SW2 rw — RSVD for sotfware
  [15] BT_WAKE_HOST_POL rw — 1:BT_WAKE_HOST to CPU and pinmux 0:pinmux to CPU for external trig
  [14] HOST_WAKE_BT_POL rw — 1:HOST_WAKE_BT to BT and pinmux 0:pinmux to BT for external trig
  [13] HOST_WAKE_BT rw — CPU set this bit to 1 to wake BT
  [12:10] BT_XTAL_MODE_LPS rw — SET XTAL state when BT in LPS mode 000: XTAL OFF 001: XTAL LPS, gating XTAL 40M 010: XTAL LPS, enable XTAL 40M 011: XTAL NM mode 100: XTAL HP mode
  [9] BT_I2C_TEST_EN rw — SW control BT enter I2C test mode
  [8:6] BT_MEM_PWRC_LPS rw — BT DMEM/BFMEM power mode control in SLEEP. Setted before chip goes to SLEEP.Used to controll power mode of BT memory group when chip is in SLEEP. For FTC_ULP mem, pwr_lps[2:0] map to {SLP,RET,NAP}; For SNPS mem, pwr_lps[2:0] map to {SD,DS,LS}. 000 - active 001 - light sleep 010 - deep sleep 100 - shut down
  [5] SET_BT_OFF_PARAM rw — level -> pulse. Write to 1 to disable XTAL and SWR, before BT OFF. Before Write to 1 or after BT OFF,need to write to 0
  [4] BT_SYS_BTDBG_SEL rw — 0: select debug port from BTTOP 1: debug_port[31:18] from bt_misc; else from BTTOP
  [3] DSWR_REF_BT rw — core swr parameter refer BT status
  [2:0] BT_SWR_STS_LPS rw — SET SWR state when BT in LPS mode 000: RSVD 001: state1 0.7/PC/PFM 010: state2 0.8/PC/PFM 011: state3 0.9/PC/PFM 100: state4 0.9/SLP/PFM 101: state5 0.9/SLP/PWM 110: state6 0.9/NORM/PWM 111: state7 1.0/NORM/PWM
0xBC REG_BT_CTRL1 access per field reset 0x8000
  [15] BT_CKSL_CKANA rw — 1: enable osc4m when BT enter LPS 0: switch bt_ana_clk from osc4m to ana_100k when BT enter LPS
  [14:0] BT_PMC_STATE ro — indicate bt_misc PMC current state, for debug
0xC0 REG_I2C_CTRL
  [3] i2c1_rx_swap — I2C1 RX swap control
  [2] i2c1_tx_swap — I2C1 TX swap control
  [1] i2c0_rx_swap — I2C0 RX swap control
  [0] i2c0_tx_swap — I2C0 TX swap control
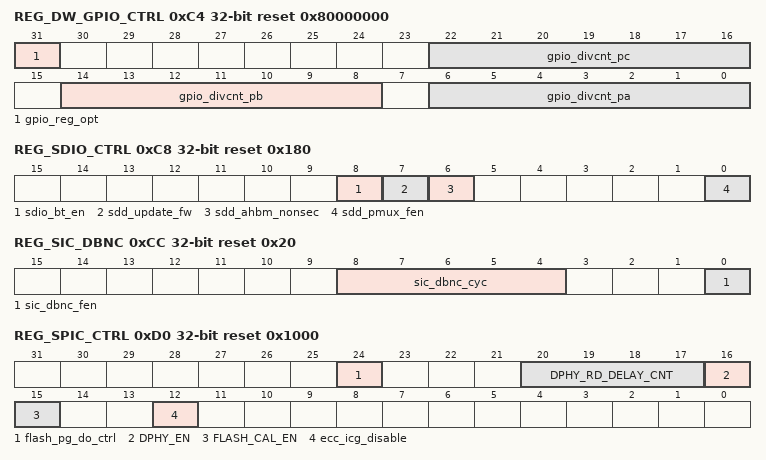
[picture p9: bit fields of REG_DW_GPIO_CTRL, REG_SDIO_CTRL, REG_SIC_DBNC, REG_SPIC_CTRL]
0xC4 REG_DW_GPIO_CTRL reset 0x80000000
  [31] gpio_reg_opt — gpio data out/oe register function option 0: DR/DDR reg function are same as DW GPIO spec 1: DR/DDR reg func changes , 0:not toggle , 1:toggle current value
  [22:16] gpio_divcnt_pc — divider for dw gpioc debounce clk
  [14:8] gpio_divcnt_pb — divider for dw gpiob debounce clk
  [6:0] gpio_divcnt_pa — divider for dw gpioa debounce clk
0xC8 REG_SDIO_CTRL reset 0x180
  [8] sdio_bt_en — enable sdio bt function(fn2)
  [7] sdd_update_fw — enable updating firmware via sdio
  [6] sdd_ahbm_nonsec — sdio wifi ahb mster 0: sec, 1: non-sec,
  [0] sdd_pmux_fen — after sdio pinmux is configured, set this bit to 1
0xCC REG_SIC_DBNC reset 0x20
  [8:4] sic_dbnc_cyc — SIC clk/data input debounce cycle , base on 4M clock
  [0] sic_dbnc_fen — SIC clk/data input debounce enable
0xD0 REG_SPIC_CTRL reset 0x1000
  [24] flash_pg_do_ctrl — 1: disable spic do output enable
  [20:17] DPHY_RD_DELAY_CNT — spic_dphy output dealy cnt, when set < 3, output data will occur at fourth or fifth axi clock from the rising edge of spi_rx_data_en; when set >= 3, data will occur after DPHY_RD_DELAY_CNT + 2 axi clock from the rising edge of spi_rx_data_en
  [16] DPHY_EN — when set, enable spic_dphy function to read data from flash
  [15] FLASH_CAL_EN — Flash calibration enable 1: delay flash sout for calibration 0: bypass flash sout to spic
  [12] ecc_icg_disable — Disable NAND ECC auto icg to save power 1:disable , no gating 0:enable
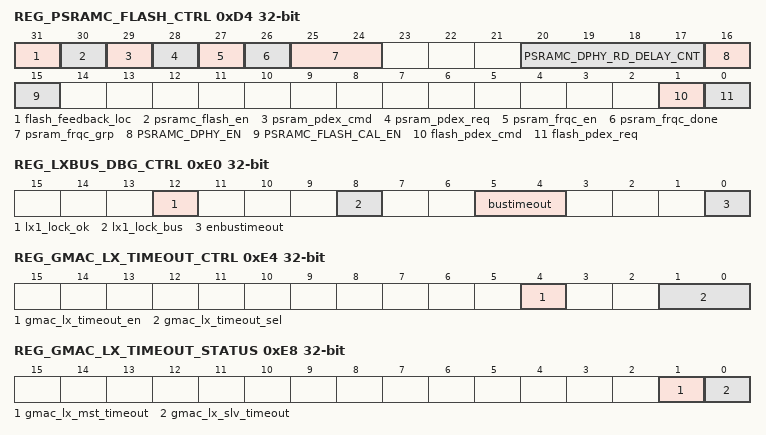
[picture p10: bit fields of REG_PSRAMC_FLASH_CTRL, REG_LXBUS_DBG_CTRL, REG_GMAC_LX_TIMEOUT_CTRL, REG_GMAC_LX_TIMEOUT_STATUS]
0xD4 REG_PSRAMC_FLASH_CTRL access per field
  [31] flash_feedback_loc rw — 0: pinmux S0 -> flash_spic, pinmux S1 -> psram_spic(if psramc_flash_en) 1: pinmux S1 -> flash_spic, pinmux S0 -> psram_spic(if psramc_flash_en)
  [30] psramc_flash_en rw — use psram_spic as flash controller, disable psram_phy
  [29] psram_pdex_cmd rw — psram_spic excute this cmd when receiving pdex_req 1: enter low power state 0: exit low power state
  [28] psram_pdex_req rw — write 1 to trigger psram_spic excuting pdex_cmd, auto clear 0 when pdex_cmd is done
  [27] psram_frqc_en rw — enable psram auto freq change control flow
  [26] psram_frqc_done ro — indicate psram auto freq change is done
  [25:24] psram_frqc_grp rw — select psram auto freq change group
  [20:17] PSRAMC_DPHY_RD_DELAY_CNT rw — spic_dphy output dealy cnt, when set < 3, output data will occur at fourth or fifth axi clock from the rising edge of spi_rx_data_en; when set >= 3, data will occur after DPHY_RD_DELAY_CNT + 2 axi clock from the rising edge of spi_rx_data_en
  [16] PSRAMC_DPHY_EN rw — when set, enable spic_dphy function to read data from flash
  [15] PSRAMC_FLASH_CAL_EN rw — Flash calibration enable 1: delay flash sout for calibration 0: bypass flash sout to spic
  [1] flash_pdex_cmd rw — flash_spic excute this cmd when receiving pdex_req 1: enter low power state 0: exit low power state
  [0] flash_pdex_req rw — write 1 to trigger flash_spic excuting pdex_cmd, auto clear 0 when pdex_cmd is done
0xDC REG_SOFT_DUMMY
  [31:0] dummy — USED for SW
0xE0 REG_LXBUS_DBG_CTRL access per field
  [12] lx1_lock_ok ro — lock lx1 bus lock ok
  [8] lx1_lock_bus rw — lock lx1 bus for debug
  [5:4] bustimeout rw — lx sys bus arb timeout thresh
  [0] enbustimeout rw — lx sys bus arb timeout enable
0xE4 REG_GMAC_LX_TIMEOUT_CTRL
  [4] gmac_lx_timeout_en — lxbus timeout enable in gmac
  [1:0] gmac_lx_timeout_sel — sel lxbus tiomeout in gmac
0xE8 REG_GMAC_LX_TIMEOUT_STATUS ro
  [1] gmac_lx_mst_timeout — lxbus master timeout status in gmac
  [0] gmac_lx_slv_timeout — lxbus slave timeout status in gmac
0xEC REG_DUMMY_P1
  [31:0] dummy — USED for SW
0xF0 REG_BOOT_ADDR_KM4TZ
  [31:0] dummy — USED for SW
0xF4 REG_BOOT_ADDR_KM4NS
  [31:0] dummy — USED for SW
0xF8 REG_DUMMY_09 reset 0xBDC10512
  [31:0] dummy — HW used only , Used for access boundary check, SYSON is 512B which is 000-1FF.
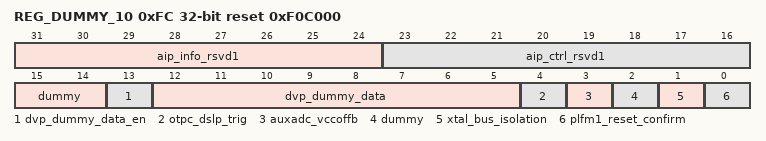
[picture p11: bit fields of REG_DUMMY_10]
0xFC REG_DUMMY_10 access per field reset 0xF0C000
  [31:24] aip_info_rsvd1 ro — reserved for aip info indication
  [23:16] aip_ctrl_rsvd1 rw — reserved for aip info indication
  [15:14] dummy rw — Reserved for HW ECO
  [13] dvp_dummy_data_en rw — dvp dummy data enable 1: enable extra dummy data fliter, only work in the end of frame 0: disable extra dummy data fliter, only flitir out 0xffff
  [12:5] dvp_dummy_data rw
  [4] otpc_dslp_trig wo — It can trig OTP to accelerate power-off.
  [3] auxadc_vccoffb rw — 1: enable auxadc power cut 0: shutdown auxadc all power cut for power saving when scan mode , it will tie0, also ISO signal must tie 1
  [2] dummy rw — Reserved for HW ECO
  [1] xtal_bus_isolation rw — plfm1 write to xtal bus isoable enable. 1: disable bus access 0: enable bus access Note: this bit only assert when plfm1 pre-reset happen to protect bus mistake
  [0] plfm1_reset_confirm rw — cpu0 write this bit to 1 to confirm plfm1 reset enable.
